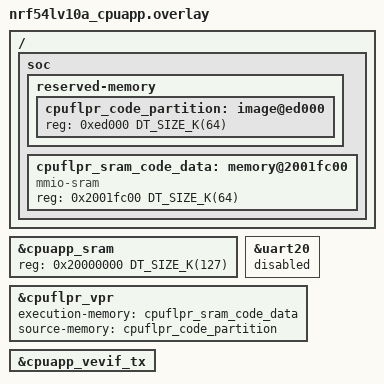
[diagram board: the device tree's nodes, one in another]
/*
 * Copyright (c) 2025 Nordic Semiconductor
 * SPDX-License-Identifier: LicenseRef-Nordic-5-Clause
 */

/ {
	soc {
		reserved-memory {
			#address-cells = <1>;
			#size-cells = <1>;

			cpuflpr_code_partition: image@ed000 {
				/* FLPR core code partition */
				reg = <0xed000 DT_SIZE_K(64)>;
			};
		};

		cpuflpr_sram_code_data: memory@2001fc00 {
			compatible = "mmio-sram";
			reg = <0x2001fc00 DT_SIZE_K(64)>;
			#address-cells = <1>;
			#size-cells = <1>;
			ranges = <0x0 0x2001fc00 DT_SIZE_K(64)>;
		};
	};
};

&cpuapp_sram {
	reg = <0x20000000 DT_SIZE_K(127)>;
	ranges = <0x0 0x20000000 DT_SIZE_K(127)>;
};

&uart20 {
	status = "reserved";
};

&cpuflpr_vpr {
	execution-memory = <&cpuflpr_sram_code_data>;
	source-memory = <&cpuflpr_code_partition>;
};

&cpuapp_vevif_tx {
	status = "okay";
};
